# MK66F18 register map
Vendor: Freescale Semiconductor, Inc.; Series: Kinetis_K; File version: 1.6
CPU: CM4 r0p1, little endian, no MPU, FPU, VTOR, 4 interrupt priority bits
Registers are 32-bit, read-write, reset 0x0 unless marked. A register's access mark holds for its fields unless they carry their own. Offsets are from the block's base; [hi:lo] are bit positions; {n}, {i} and the like mark numbered series; 'fields as' and 'values as' point back to an identical list.

## SIM — System Integration Module
Base 0x40047000; register names take the prefix SIM_
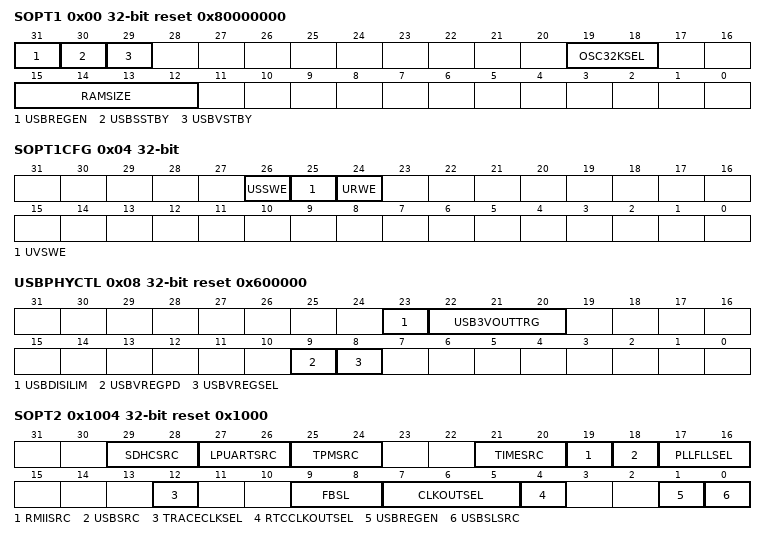
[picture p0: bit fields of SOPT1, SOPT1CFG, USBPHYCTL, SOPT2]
0x00 SOPT1 reset 0x80000000 (reset mask 0xFFFF0FC0) — System Options Register 1
  [31] USBREGEN — USB voltage regulator enable
    0=USB voltage regulator is disabled; 1=USB voltage regulator is enabled
  [30] USBSSTBY — USB voltage regulator in standby mode during Stop, VLPS, LLS and VLLS modes.
    0=USB voltage regulator not in standby during Stop, VLPS, LLS and VLLS modes; 1=USB voltage regulator in standby during Stop, VLPS, LLS and VLLS modes
  [29] USBVSTBY — USB voltage regulator in standby mode during VLPR and VLPW modes
    0=USB voltage regulator not in standby during VLPR and VLPW modes; 1=USB voltage regulator in standby during VLPR and VLPW modes
  [19:18] OSC32KSEL — 32K oscillator clock select
    0=System oscillator (OSC32KCLK); 2=RTC 32.768kHz oscillator; 3=LPO 1 kHz
  [15:12] RAMSIZE ro
    1=8 KB; 3=16 KB; 4=24 KB; 5=32 KB; 6=48 KB; 7=64 KB; 8=96 KB; 9=128 KB; 11=256 KB
0x04 SOPT1CFG — SOPT1 Configuration Register
  [26] USSWE — USB voltage regulator stop standby write enable
    0=SOPT1 USBSSTBY cannot be written; 1=SOPT1 USBSSTBY can be written
  [25] UVSWE — USB voltage regulator VLP standby write enable
    0=SOPT1 USBVSTBY cannot be written; 1=SOPT1 USBVSTBY can be written
  [24] URWE — USB voltage regulator enable write enable
    0=SOPT1 USBREGEN cannot be written; 1=SOPT1 USBREGEN can be written
0x08 USBPHYCTL reset 0x600000 — USB PHY Control Register
  [23] USBDISILIM — USB Disable Inrush Current Limit
    0=The current limiter for the USB Voltage Regulator is enabled; 1=The current limiter for the USB Voltage Regulator is disabled
  [22:20] USB3VOUTTRG — USB 3.3V Output Target
    0=2.733V; 1=3.020V; 2=3.074V; 3=3.130V; 4=3.188V; 5=3.248V; 6=3.310V (default); 7=3.662V (For Freescale use only, not for customer use)
  [9] USBVREGPD — Enables the pulldown on the output of the USB Regulator.
    0=Regulator output pulldown resistor is not enabled; 1=Regulator output pulldown resistor is enabled
  [8] USBVREGSEL — Selects the default input voltage source to the USB Regulator in case both VREG_IN0 and VREG_IN1 are powered
    0=VREG_IN0 will be selected if both regulator inputs are powered; 1=VREG_IN1 will be selected if both regulator inputs are powered
0x1004 SOPT2 reset 0x1000 — System Options Register 2
  [29:28] SDHCSRC — SDHC clock source select
    0=Core/system clock; 1=MCGFLLCLK, or MCGPLLCLK , or IRC48M , or USB1 PFD clock as selected by SOPT2[PLLFLLSEL]; 2=OSCERCLK clock; 3=External bypass clock (SDHC0_CLKIN)
  [27:26] LPUARTSRC — LPUART clock source select
    0=Clock disabled; 1=MCGFLLCLK , or MCGPLLCLK , or IRC48M , or USB1 PFD clock as selected by SOPT2[PLLFLLSEL], and then divided by the PLLFLLCLK fractional divider as configured by SIM_CLKDIV3[PLLFLLFRAC, PLLFLLDIV]; 2=OSCERCLK clock; 3=MCGIRCLK clock
  [25:24] TPMSRC — TPM clock source select
    values as LPUARTSRC
  [21:20] TIMESRC — IEEE 1588 timestamp clock source select
    0=Core/system clock; 1=MCGFLLCLK , or MCGPLLCLK , or IRC48M , or USB1 PFD clock as selected by SOPT2[PLLFLLSEL]; 2=OSCERCLK clock; 3=External bypass clock (ENET_1588_CLKIN)
  [19] RMIISRC — RMII clock source select
    0=EXTAL clock; 1=External bypass clock (ENET_1588_CLKIN)
  [18] USBSRC — USB clock source select
    0=External bypass clock (USB_CLKIN); 1=MCGFLLCLK, or MCGPLLCLK , or IRC48M , or USB1 PFD clock as selected by SOPT2[PLLFLLSEL], and then divided by the USB fractional divider as configured by SIM_CLKDIV2[USBFRAC, USBDIV]
  [17:16] PLLFLLSEL — PLL/FLL clock select
    0=MCGFLLCLK clock; 1=MCGPLLCLK clock; 2=USB1 PFD clock; 3=IRC48 MHz clock
  [12] TRACECLKSEL — Debug trace clock select
    0=MCGOUTCLK, divided by the TRACECLK fractional divider as configured by SIM_CLKDIV4[TRACEFRAC, TRACEDIV]; 1=Core/system clock
  [9:8] FBSL — FlexBus security level
    0=All off-chip accesses (instruction and data) via the FlexBus or SDRAM are disallowed; 1=All off-chip accesses (instruction and data) via the FlexBus or SDRAM are disallowed; 2=Off-chip instruction accesses are disallowed. Data accesses are allowed.; 3=Off-chip instruction accesses and data accesses are allowed
  [7:5] CLKOUTSEL — CLKOUT select
    0=FlexBus CLKOUT; 2=Flash clock; 3=LPO clock (1 kHz); 4=MCGIRCLK; 5=RTC 32.768kHz clock; 6=OSCERCLK0; 7=IRC 48 MHz clock
  [4] RTCCLKOUTSEL — RTC clock out select
    0=RTC 1 Hz clock is output on the RTC_CLKOUT pin; 1=RTC 32.768kHz clock is output on the RTC_CLKOUT pin
  [1] USBREGEN — USB PHY PLL Regulator Enable
    0=USB PHY PLL Regulator disabled; 1=USB PHY PLL Regulator enabled
  [0] USBSLSRC — USB Slow Clock Source
    0=MCGIRCLK; 1=RTC 32.768kHz clock
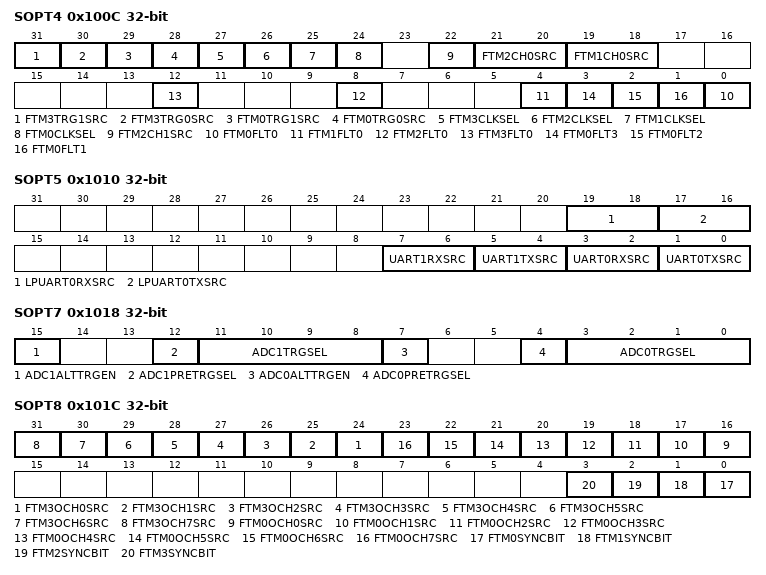
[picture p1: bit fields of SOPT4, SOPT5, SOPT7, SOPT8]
0x100C SOPT4 — System Options Register 4
  [31] FTM3TRG1SRC — FlexTimer 3 Hardware Trigger 1 Source Select
    1=FTM2 channel match drives FTM3 hardware trigger 1
  [30] FTM3TRG0SRC — FlexTimer 3 Hardware Trigger 0 Source Select
    1=FTM1 channel match drives FTM3 hardware trigger 0
  [29] FTM0TRG1SRC — FlexTimer 0 Hardware Trigger 1 Source Select
    0=PDB output trigger 1 drives FTM0 hardware trigger 1; 1=FTM2 channel match drives FTM0 hardware trigger 1
  [28] FTM0TRG0SRC — FlexTimer 0 Hardware Trigger 0 Source Select
    0=HSCMP0 output drives FTM0 hardware trigger 0; 1=FTM1 channel match drives FTM0 hardware trigger 0
  [27] FTM3CLKSEL — FlexTimer 3 External Clock Pin Select
    0=FTM3 external clock driven by FTM_CLK0 pin; 1=FTM3 external clock driven by FTM_CLK1 pin
  [26] FTM2CLKSEL — FlexTimer 2 External Clock Pin Select
    0=FTM2 external clock driven by FTM_CLK0 pin; 1=FTM2 external clock driven by FTM_CLK1 pin
  [25] FTM1CLKSEL — FTM1 External Clock Pin Select
    0=FTM_CLK0 pin; 1=FTM_CLK1 pin
  [24] FTM0CLKSEL — FlexTimer 0 External Clock Pin Select
    0=FTM_CLK0 pin; 1=FTM_CLK1 pin
  [22] FTM2CH1SRC — FTM2 channel 1 input capture source select
    0=FTM2_CH1 signal; 1=Exclusive OR of FTM2_CH1, FTM2_CH0 and FTM1_CH1
  [21:20] FTM2CH0SRC — FTM2 channel 0 input capture source select
    0=FTM2_CH0 signal; 1=CMP0 output; 2=CMP1 output
  [19:18] FTM1CH0SRC — FTM1 channel 0 input capture source select
    0=FTM1_CH0 signal; 1=CMP0 output; 2=CMP1 output; 3=USB start of frame pulse
  [4n] FTM{n}FLT0 (n=0..3) — FTM{n} Fault 0 Select
    0=FTM{n}_FLT0 pin; 1=CMP0 out
  [3] FTM0FLT3 — FTM0 Fault 3 Select
    0=FTM0_FLT3 pin; 1=CMP3 out
  [2] FTM0FLT2 — FTM0 Fault 2 Select
    0=FTM0_FLT2 pin; 1=CMP2 out
  [1] FTM0FLT1 — FTM0 Fault 1 Select
    0=FTM0_FLT1 pin; 1=CMP1 out
0x1010 SOPT5 — System Options Register 5
  [19:18] LPUART0RXSRC — LPUART0 receive data source select
    0=LPUART0_RX pin; 1=CMP0 output; 2=CMP1 output
  [17:16] LPUART0TXSRC — LPUART0 transmit data source select
    0=LPUART0_TX pin; 1=LPUART0_TX pin modulated with TPM1 channel 0 output; 2=LPUART0_TX pin modulated with TPM2 channel 0 output
  [7:6] UART1RXSRC — UART 1 receive data source select
    0=UART1_RX pin; 1=CMP0; 2=CMP1
  [5:4] UART1TXSRC — UART 1 transmit data source select
    0=UART1_TX pin; 1=UART1_TX pin modulated with FTM1 channel 0 output; 2=UART1_TX pin modulated with FTM2 channel 0 output
  [3:2] UART0RXSRC — UART 0 receive data source select
    0=UART0_RX pin; 1=CMP0; 2=CMP1
  [1:0] UART0TXSRC — UART 0 transmit data source select
    0=UART0_TX pin; 1=UART0_TX pin modulated with FTM1 channel 0 output; 2=UART0_TX pin modulated with FTM2 channel 0 output
0x1018 SOPT7 — System Options Register 7
  [15] ADC1ALTTRGEN — ADC1 alternate trigger enable
    0=PDB trigger selected for ADC1; 1=Alternate trigger selected for ADC1 as defined by ADC1TRGSEL
  [12] ADC1PRETRGSEL — ADC1 pre-trigger select
    0=Pre-trigger A selected for ADC1; 1=Pre-trigger B selected for ADC1
  [11:8] ADC1TRGSEL — ADC1 trigger select
    0=PDB external trigger pin input (PDB0_EXTRG); 1=High speed comparator 0 output; 2=High speed comparator 1 output; 3=High speed comparator 2 output; {v}=PIT trigger {v-4} (v=4..7); {v}=FTM{v-8} trigger (v=8..11); 12=RTC alarm; 13=RTC seconds; 14=Low-power timer (LPTMR) trigger; 15=TPM2 channel 0 (A pretrigger) and channel 1 (B pretrigger)
  [7] ADC0ALTTRGEN — ADC0 alternate trigger enable
    0=PDB trigger selected for ADC0; 1=Alternate trigger selected for ADC0
  [4] ADC0PRETRGSEL — ADC0 pretrigger select
    0=Pre-trigger A; 1=Pre-trigger B
  [3:0] ADC0TRGSEL — ADC0 trigger select
    0=PDB external trigger pin input (PDB0_EXTRG); 1=High speed comparator 0 output; 2=High speed comparator 1 output; 3=High speed comparator 2 output; {v}=PIT trigger {v-4} (v=4..7); {v}=FTM{v-8} trigger (v=8..11); 12=RTC alarm; 13=RTC seconds; 14=Low-power timer (LPTMR) trigger; 15=TPM1 channel 0 (A pretrigger) and channel 1 (B pretrigger)
0x101C SOPT8 — System Options Register 8
  [n+24] FTM3OCH{n}SRC (n=0..7) — FTM3 channel {n} output source
    0=FTM3_CH{n} pin is output of FTM3 channel {n} output; 1=FTM3_CH{n} pin is output of FTM3 channel {n} output modulated by FTM2 channel 1 output
  [n+16] FTM0OCH{n}SRC (n=0..7) — FTM0 channel {n} output source
    0=FTM0_CH{n} pin is output of FTM0 channel {n} output; 1=FTM0_CH{n} pin is output of FTM0 channel {n} output, modulated by FTM1 channel 1 output
  [n] FTM{n}SYNCBIT (n=0..3) — FTM{n} Hardware Trigger 0 Software Synchronization
    0=No effect; 1=Write 1 to assert the TRIG0 input to FTM{n}, software must clear this bit to allow other trigger sources to assert
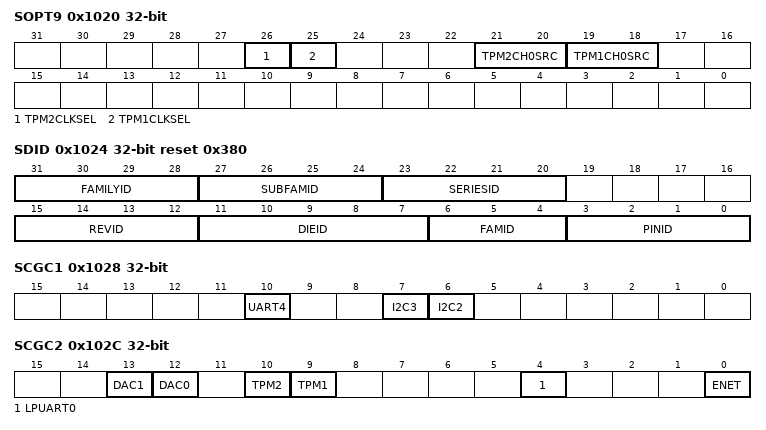
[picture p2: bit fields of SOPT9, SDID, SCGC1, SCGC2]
0x1020 SOPT9 — System Options Register 9
  [26] TPM2CLKSEL — TPM2 External Clock Pin Select
    0=TPM_CLKIN0 pin; 1=TPM_CLKIN1 pin
  [25] TPM1CLKSEL — TPM1 External Clock Pin Select
    0=TPM_CLKIN0 pin; 1=TPM_CLKIN1 pin
  [21:20] TPM2CH0SRC — TPM2 channel 0 input capture source select
    0=TPM2_CH0 signal; 1=CMP0 output; 2=CMP1 output
  [19:18] TPM1CH0SRC — TPM1 channel 0 input capture source select
    0=TPM1_CH0 signal; 1=CMP0 output; 2=CMP1 output
0x1024 SDID ro reset 0x380 (reset mask 0xF0F80) — System Device Identification Register
  [31:28] FAMILYID — Kinetis Family ID
    {v}=K{v}x Family (v=0..4); 6=K6x Family; 7=K7x Family; 8=K8x Family
  [27:24] SUBFAMID — Kinetis Sub-Family ID
    0=Kx0 Subfamily; 1=Kx1 Subfamily (tamper detect); 2=Kx2 Subfamily; 3=Kx3 Subfamily (tamper detect); 4=Kx4 Subfamily; 5=Kx5 Subfamily (tamper detect); 6=Kx6 Subfamily
  [23:20] SERIESID — Kinetis Series ID
    0=Kinetis K series; 1=Kinetis L series; 5=Kinetis W series; 6=Kinetis V series
  [15:12] REVID — Device revision number
  [11:7] DIEID — Device Die ID
  [6:4] FAMID — Kinetis family identification
    0=K1x Family (without tamper); 1=K2x Family (without tamper); 2=K3x Family or K1x/K6x Family (with tamper); 3=K4x Family or K2x Family (with tamper); 4=K6x Family (without tamper); 5=K7x Family
  [3:0] PINID — Pincount identification
    2=32-pin; 4=48-pin; 5=64-pin; 6=80-pin; 7=81-pin or 121-pin; 8=100-pin; 9=121-pin; 10=144-pin; 11=Custom pinout (WLCSP); 12=169-pin; 14=256-pin
0x1028 SCGC1 — System Clock Gating Control Register 1
  [all] fields
    0=Clock disabled; 1=Clock enabled
  [10] UART4 — UART4 Clock Gate Control
  [7] I2C3 — I2C3 Clock Gate Control
  [6] I2C2 — I2C2 Clock Gate Control
0x102C SCGC2 — System Clock Gating Control Register 2
  [all] fields
    0=Clock disabled; 1=Clock enabled
  [13] DAC1 — DAC1 Clock Gate Control
  [12] DAC0 — DAC0 Clock Gate Control
  [10] TPM2 — TPM2 Clock Gate Control
  [9] TPM1 — TPM1 Clock Gate Control
  [4] LPUART0 — LPUART0 Clock Gate Control
  [0] ENET — ENET Clock Gate Control
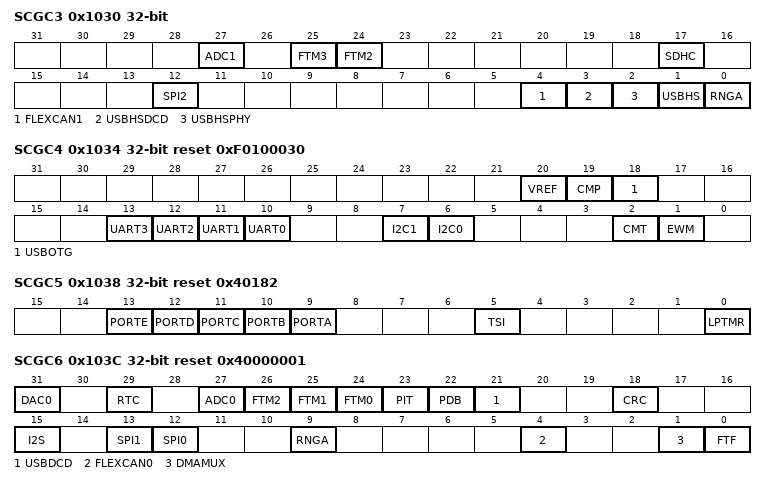
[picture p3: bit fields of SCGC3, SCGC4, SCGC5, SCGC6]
0x1030 SCGC3 — System Clock Gating Control Register 3
  [all] fields
    0=Clock disabled; 1=Clock enabled
  [27] ADC1 — ADC1 Clock Gate Control
  [25] FTM3 — FTM3 Clock Gate Control
  [24] FTM2 — FTM2 Clock Gate Control
  [17] SDHC — SDHC Clock Gate Control
  [12] SPI2 — SPI2 Clock Gate Control
  [4] FLEXCAN1 — FlexCAN1 Clock Gate Control
  [3] USBHSDCD — USBHS DCD Clock Gate Control
  [2] USBHSPHY — USBHS PHY Clock Gate Control
  [1] USBHS — USBHS Clock Gate Control
  [0] RNGA — RNGA Clock Gate Control
0x1034 SCGC4 reset 0xF0100030 — System Clock Gating Control Register 4
  [all] fields
    0=Clock disabled; 1=Clock enabled
  [20] VREF — VREF Clock Gate Control
  [19] CMP — Comparator Clock Gate Control
  [18] USBOTG — USB Clock Gate Control
  [n+10] UART{n} (n=0..3) — UART{n} Clock Gate Control
  [7] I2C1 — I2C1 Clock Gate Control
  [6] I2C0 — I2C0 Clock Gate Control
  [2] CMT — CMT Clock Gate Control
  [1] EWM — EWM Clock Gate Control
0x1038 SCGC5 reset 0x40182 — System Clock Gating Control Register 5
  [13] PORTE — Port E Clock Gate Control
    0=Clock disabled; 1=Clock enabled
  [12] PORTD — Port D Clock Gate Control
    0=Clock disabled; 1=Clock enabled
  [11] PORTC — Port C Clock Gate Control
    0=Clock disabled; 1=Clock enabled
  [10] PORTB — Port B Clock Gate Control
    0=Clock disabled; 1=Clock enabled
  [9] PORTA — Port A Clock Gate Control
    0=Clock disabled; 1=Clock enabled
  [5] TSI — TSI Clock Gate Control
    0=Clock disabled; 1=Clock enabled
  [0] LPTMR — Low Power Timer Access Control
    0=Access disabled; 1=Access enabled
0x103C SCGC6 reset 0x40000001 — System Clock Gating Control Register 6
  [31] DAC0 — DAC0 Clock Gate Control
    0=Clock disabled; 1=Clock enabled
  [29] RTC — RTC Access Control
    0=Access and interrupts disabled; 1=Access and interrupts enabled
  [27] ADC0 — ADC0 Clock Gate Control
    0=Clock disabled; 1=Clock enabled
  [26] FTM2 — FTM2 Clock Gate Control
    0=Clock disabled; 1=Clock enabled
  [25] FTM1 — FTM1 Clock Gate Control
    0=Clock disabled; 1=Clock enabled
  [24] FTM0 — FTM0 Clock Gate Control
    0=Clock disabled; 1=Clock enabled
  [23] PIT — PIT Clock Gate Control
    0=Clock disabled; 1=Clock enabled
  [22] PDB — PDB Clock Gate Control
    0=Clock disabled; 1=Clock enabled
  [21] USBDCD — USB DCD Clock Gate Control
    0=Clock disabled; 1=Clock enabled
  [18] CRC — CRC Clock Gate Control
    0=Clock disabled; 1=Clock enabled
  [15] I2S — I2S Clock Gate Control
    0=Clock disabled; 1=Clock enabled
  [13] SPI1 — SPI1 Clock Gate Control
    0=Clock disabled; 1=Clock enabled
  [12] SPI0 — SPI0 Clock Gate Control
    0=Clock disabled; 1=Clock enabled
  [9] RNGA — RNGA Clock Gate Control
  [4] FLEXCAN0 — FlexCAN0 Clock Gate Control
    0=Clock disabled; 1=Clock enabled
  [1] DMAMUX — DMA Mux Clock Gate Control
    0=Clock disabled; 1=Clock enabled
  [0] FTF — Flash Memory Clock Gate Control
    0=Clock disabled; 1=Clock enabled
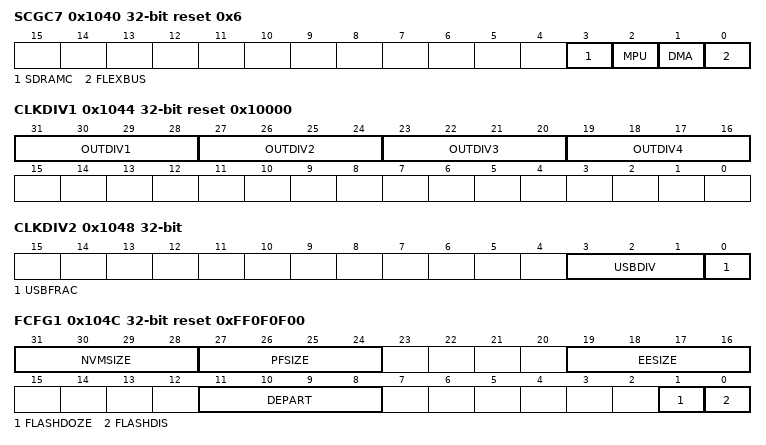
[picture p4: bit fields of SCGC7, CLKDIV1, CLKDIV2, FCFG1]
0x1040 SCGC7 reset 0x6 — System Clock Gating Control Register 7
  [all] fields
    0=Clock disabled; 1=Clock enabled
  [3] SDRAMC — SDRAMC Clock Gate Control
  [2] MPU — MPU Clock Gate Control
  [1] DMA — DMA Clock Gate Control
  [0] FLEXBUS — FlexBus Clock Gate Control
0x1044 CLKDIV1 reset 0x10000 — System Clock Divider Register 1
  [all] fields
    {v}=Divide-by-{v+1} (v=0..15)
  [35-4n:32-4n] OUTDIV{n} (n=1..4) — Clock {n} output divider value
0x1048 CLKDIV2 — System Clock Divider Register 2
  [3:1] USBDIV — USB clock divider divisor
  [0] USBFRAC — USB clock divider fraction
0x104C FCFG1 reset 0xFF0F0F00 — Flash Configuration Register 1
  [31:28] NVMSIZE ro — FlexNVM size
    0=0 KB of FlexNVM; 3=32 KB of FlexNVM; 5=64 KB of FlexNVM; 7=128 KB of FlexNVM; 9=256 KB of FlexNVM; 11=512 KB of FlexNVM; 15=256 KB of FlexNVM
  [27:24] PFSIZE ro — Program flash size
    3=32 KB of program flash memory; 5=64 KB of program flash memory; 7=128 KB of program flash memory; 9=256 KB of program flash memory; 11=512 KB of program flash memory; 13=1024 KB of program flash memory; 15=2048 KB of program flash memory
  [19:16] EESIZE ro — EEPROM size
    0=16 KB; 1=8 KB; 2=4 KB; 3=2 KB; 4=1 KB; 5=512 Bytes; 6=256 Bytes; 7=128 Bytes; 8=64 Bytes; 9=32 Bytes; 15=0 Bytes
  [11:8] DEPART ro — FlexNVM partition
  [1] FLASHDOZE
    0=Flash remains enabled during Wait mode; 1=Flash is disabled for the duration of Wait mode
  [0] FLASHDIS — Flash Disable
    0=Flash is enabled; 1=Flash is disabled
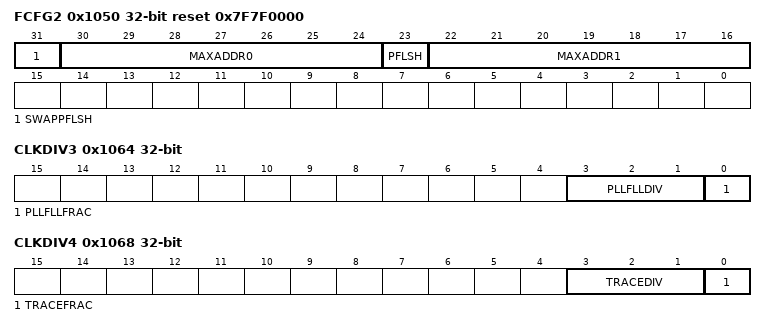
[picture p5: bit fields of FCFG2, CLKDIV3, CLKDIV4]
0x1050 FCFG2 ro reset 0x7F7F0000 — Flash Configuration Register 2
  [31] SWAPPFLSH — Swap program flash
    0=Swap is not active; 1=Swap is active
  [30:24] MAXADDR0 — Max address block 0
  [23] PFLSH — Program flash only
    0=Device supports FlexNVM; 1=Program Flash only, device does not support FlexNVM
  [22:16] MAXADDR1 — Max address block 1
0x1054 UIDH ro — Unique Identification Register High
  [31:0] UID — Unique Identification
0x1058 UIDMH ro — Unique Identification Register Mid-High
  [31:0] UID — Unique Identification
0x105C UIDML ro — Unique Identification Register Mid Low
  [31:0] UID — Unique Identification
0x1060 UIDL ro — Unique Identification Register Low
  [31:0] UID — Unique Identification
0x1064 CLKDIV3 — System Clock Divider Register 3
  [3:1] PLLFLLDIV — PLLFLL clock divider divisor
  [0] PLLFLLFRAC — PLLFLL clock divider fraction
0x1068 CLKDIV4 — System Clock Divider Register 4
  [3:1] TRACEDIV — Trace clock divider divisor
  [0] TRACEFRAC — Trace clock divider fraction
